AUTOSAR XML (schema 4-2-2)
package /ASW_COM_STD_Package
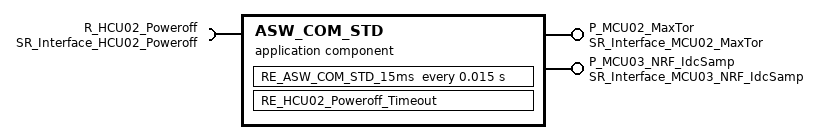
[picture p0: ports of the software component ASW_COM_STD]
  application sw component type ASW_COM_STD
    provide port P_MCU02_MaxTor: provided-interface=SR_Interface_MCU02_MaxTor
    provide port P_MCU03_NRF_IdcSamp: provided-interface=SR_Interface_MCU03_NRF_IdcSamp
    require port R_HCU02_Poweroff: required-interface=SR_Interface_HCU02_Poweroff
    sw c internal behavior IB_ASW_COM_STD
      timing event TE_15ms_RE_ASW_COM_STD: start-on-event=RE_ASW_COM_STD_15ms, period=0.015
      data receive error event DREE_R_HCU02_Poweroff: start-on-event=RE_HCU02_Poweroff_Timeout, alive-timeout=0.3, data=R_HCU02_Poweroff.HCU02_Poweroff
      runnable RE_ASW_COM_STD_15ms
        data-read-access:
          access READ_R_HCU02_Poweroff: accessed-variable=R_HCU02_Poweroff.HCU02_Poweroff
        data-write-access:
          access WRITE_P_MCU02_MaxTor: accessed-variable=P_MCU02_MaxTor.MCU02_MaxTor
          access WRITE_P_MCU03_NRF_IdcSamp: accessed-variable=P_MCU03_NRF_IdcSamp.MCU03_NRF_IdcSamp
      runnable RE_HCU02_Poweroff_Timeout
